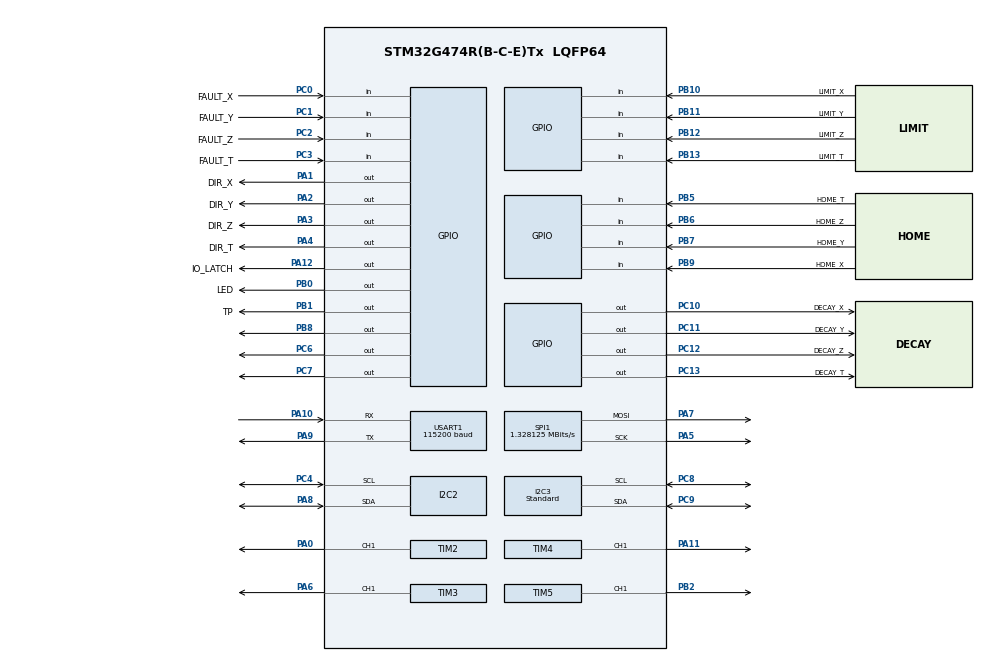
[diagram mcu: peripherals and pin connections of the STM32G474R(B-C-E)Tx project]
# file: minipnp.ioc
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Dma.Request0=USART1_TX
Dma.USART1_TX.0.Direction=DMA_MEMORY_TO_PERIPH
Dma.USART1_TX.0.EventEnable=DISABLE
Dma.USART1_TX.0.Instance=DMA1_Channel1
Dma.USART1_TX.0.MemDataAlignment=DMA_MDATAALIGN_BYTE
Dma.USART1_TX.0.MemInc=DMA_MINC_ENABLE
Dma.USART1_TX.0.Mode=DMA_NORMAL
Dma.USART1_TX.0.PeriphDataAlignment=DMA_PDATAALIGN_BYTE
Dma.USART1_TX.0.PeriphInc=DMA_PINC_DISABLE
Dma.USART1_TX.0.Polarity=HAL_DMAMUX_REQ_GEN_RISING
Dma.USART1_TX.0.Priority=DMA_PRIORITY_LOW
Dma.USART1_TX.0.RequestNumber=1
Dma.USART1_TX.0.SignalID=NONE
Dma.USART1_TX.0.SyncEnable=DISABLE
Dma.USART1_TX.0.SyncPolarity=HAL_DMAMUX_SYNC_NO_EVENT
Dma.USART1_TX.0.SyncRequestNumber=1
Dma.USART1_TX.0.SyncSignalID=NONE
I2C2.Timing=0x30A0A7FB
I2C3.CustomTiming=Disabled
I2C3.I2C_Speed_Mode=I2C_Standard
I2C3.Timing=0x30A0A7FB
Mcu.Family=STM32G4
Mcu.Name=STM32G474R(B-C-E)Tx
Mcu.Package=LQFP64
NVIC.DMA1_Channel1_IRQn=true\:0\:0\:false\:false\:true\:false\:true
NVIC.PriorityGroup=NVIC_PRIORITYGROUP_4
NVIC.TIM2_IRQn=true\:0\:0\:false\:false\:true\:true\:true
NVIC.TIM3_IRQn=true\:0\:0\:false\:false\:true\:true\:true
NVIC.TIM4_IRQn=true\:0\:0\:false\:false\:true\:true\:true
NVIC.TIM5_IRQn=true\:0\:0\:false\:false\:true\:true\:true
NVIC.TIM6_DAC_IRQn=true\:1\:0\:true\:false\:true\:true\:true
NVIC.USART1_IRQn=true\:2\:0\:true\:false\:true\:true\:true
PA0.Signal=S_TIM2_CH1
PA1.GPIO_Label=DIR_X
PA1.GPIO_Speed=GPIO_SPEED_FREQ_VERY_HIGH
PA1.Signal=GPIO_Output
PA10.Mode=Asynchronous
PA10.Signal=USART1_RX
PA11.Signal=S_TIM4_CH1
PA12.GPIO_Label=IO_LATCH
PA12.GPIO_Speed=GPIO_SPEED_FREQ_VERY_HIGH
PA12.Signal=GPIO_Output
PA13.Mode=JTAG_5_pins
PA13.Signal=SYS_JTMS-SWDIO
PA14.Mode=JTAG_5_pins
PA14.Signal=SYS_JTCK-SWCLK
PA15.Mode=JTAG_5_pins
PA15.Signal=SYS_JTDI
PA2.GPIO_Label=DIR_Y
PA2.GPIO_Speed=GPIO_SPEED_FREQ_VERY_HIGH
PA2.Signal=GPIO_Output
PA3.GPIO_Label=DIR_Z
PA3.GPIO_Speed=GPIO_SPEED_FREQ_VERY_HIGH
PA3.Signal=GPIO_Output
PA4.GPIO_Label=DIR_T
PA4.GPIO_Speed=GPIO_SPEED_FREQ_VERY_HIGH
PA4.Signal=GPIO_Output
PA5.Mode=TX_Only_Simplex_Unidirect_Master
PA5.Signal=SPI1_SCK
PA6.Signal=S_TIM3_CH1
PA7.Mode=TX_Only_Simplex_Unidirect_Master
PA7.Signal=SPI1_MOSI
PA8.GPIO_Pu=GPIO_PULLUP
PA8.Mode=I2C
PA8.Signal=I2C2_SDA
PA9.Mode=Asynchronous
PA9.Signal=USART1_TX
PB0.GPIO_Label=LED
PB0.GPIO_Speed=GPIO_SPEED_FREQ_VERY_HIGH
PB0.Signal=GPIO_Output
PB1.GPIO_Label=TP
PB1.GPIO_Speed=GPIO_SPEED_FREQ_VERY_HIGH
PB1.Signal=GPIO_Output
PB10.GPIO_Label=LIMIT_X
PB10.Signal=GPIO_Input
PB11.GPIO_Label=LIMIT_Y
PB11.Signal=GPIO_Input
PB12.GPIO_Label=LIMIT_Z
PB12.Signal=GPIO_Input
PB13.GPIO_Label=LIMIT_T
PB13.Signal=GPIO_Input
PB2.Signal=S_TIM5_CH1
PB3.Mode=JTAG_5_pins
PB3.Signal=SYS_JTDO-SWO
PB4.Mode=JTAG_5_pins
PB4.Signal=SYS_JTRST
PB5.GPIO_Label=HOME_T
PB5.Signal=GPIO_Input
PB6.GPIO_Label=HOME_Z
PB6.Signal=GPIO_Input
PB7.GPIO_Label=HOME_Y
PB7.Signal=GPIO_Input
PB8-BOOT0.Signal=GPIO_Output
PB9.GPIO_Label=HOME_X
PB9.Signal=GPIO_Input
PC0.GPIO_Label=FAULT_X
PC0.Signal=GPIO_Input
PC1.GPIO_Label=FAULT_Y
PC1.Signal=GPIO_Input
PC10.GPIO_Label=DECAY_X
PC10.Signal=GPIO_Output
PC11.GPIO_Label=DECAY_Y
PC11.Signal=GPIO_Output
PC12.GPIO_Label=DECAY_Z
PC12.Signal=GPIO_Output
PC13.GPIO_Label=DECAY_T
PC13.PinState=GPIO_PIN_RESET
PC13.Signal=GPIO_Output
PC2.GPIO_Label=FAULT_Z
PC2.Signal=GPIO_Input
PC3.GPIO_Label=FAULT_T
PC3.Signal=GPIO_Input
PC4.GPIO_Pu=GPIO_PULLUP
PC4.Mode=I2C
PC4.Signal=I2C2_SCL
PC6.Signal=GPIO_Output
PC7.Signal=GPIO_Output
PC8.GPIO_Pu=GPIO_PULLUP
PC8.Mode=I2C
PC8.Signal=I2C3_SCL
PC9.GPIO_Pu=GPIO_PULLUP
PC9.Mode=I2C
PC9.Signal=I2C3_SDA
PF0-OSC_IN.Signal=ADC1_IN10
ProjectManager.HeapSize=0x200
ProjectManager.StackSize=0x400
ProjectManager.TargetToolchain=STM32CubeIDE
RCC.ADC12Freq_Value=170000000
RCC.ADC345Freq_Value=170000000
RCC.AHBFreq_Value=170000000
RCC.APB1Freq_Value=170000000
RCC.APB1TimFreq_Value=170000000
RCC.APB2Freq_Value=170000000
RCC.APB2TimFreq_Value=170000000
RCC.CortexFreq_Value=170000000
RCC.EXTERNAL_CLOCK_VALUE=12288000
RCC.HCLKFreq_Value=170000000
RCC.HSE_VALUE=8000000
RCC.HSI48_VALUE=48000000
RCC.HSI_VALUE=16000000
RCC.LSE_VALUE=32768
RCC.PLLM=RCC_PLLM_DIV4
RCC.PLLN=85
RCC.SYSCLKFreq_VALUE=170000000
RCC.SYSCLKSource=RCC_SYSCLKSOURCE_PLLCLK
RCC.USBFreq_Value=170000000
RCC.VCOOutputFreq_Value=340000000
SH.S_TIM2_CH1.0=TIM2_CH1,PWM Generation1 CH1
SH.S_TIM3_CH1.0=TIM3_CH1,PWM Generation1 CH1
SH.S_TIM4_CH1.0=TIM4_CH1,PWM Generation1 CH1
SH.S_TIM5_CH1.0=TIM5_CH1,PWM Generation1 CH1
SPI1.BaudRatePrescaler=SPI_BAUDRATEPRESCALER_128
SPI1.CalculateBaudRate=1.328125 MBits/s
SPI1.DataSize=SPI_DATASIZE_8BIT
SPI1.Direction=SPI_DIRECTION_2LINES
SPI1.Mode=SPI_MODE_MASTER
SPI1.NSSPMode=SPI_NSS_PULSE_DISABLE
SPI1.VirtualType=VM_MASTER
TIM2.AutoReloadPreload=TIM_AUTORELOAD_PRELOAD_ENABLE
TIM2.Channel-PWM\ Generation1\ CH1=TIM_CHANNEL_1
TIM2.OC1Preload_PWM=ENABLE
TIM2.OCFastMode_PWM-PWM\ Generation1\ CH1=TIM_OCFAST_ENABLE
TIM2.OCMode_PWM-PWM\ Generation1\ CH1=TIM_OCMODE_PWM2
TIM2.OCPolarity_1=TIM_OCPOLARITY_HIGH
TIM3.AutoReloadPreload=TIM_AUTORELOAD_PRELOAD_ENABLE
TIM3.Channel-PWM\ Generation1\ CH1=TIM_CHANNEL_1
TIM3.OCFastMode_PWM-PWM\ Generation1\ CH1=TIM_OCFAST_ENABLE
TIM3.OCMode_PWM-PWM\ Generation1\ CH1=TIM_OCMODE_PWM2
TIM4.AutoReloadPreload=TIM_AUTORELOAD_PRELOAD_ENABLE
TIM4.Channel-PWM\ Generation1\ CH1=TIM_CHANNEL_1
TIM4.OCFastMode_PWM-PWM\ Generation1\ CH1=TIM_OCFAST_ENABLE
TIM4.OCMode_PWM-PWM\ Generation1\ CH1=TIM_OCMODE_PWM2
TIM5.AutoReloadPreload=TIM_AUTORELOAD_PRELOAD_ENABLE
TIM5.Channel-PWM\ Generation1\ CH1=TIM_CHANNEL_1
TIM5.OCFastMode_PWM-PWM\ Generation1\ CH1=TIM_OCFAST_ENABLE
TIM5.OCMode_PWM-PWM\ Generation1\ CH1=TIM_OCMODE_PWM2
TIM6.AutoReloadPreload=TIM_AUTORELOAD_PRELOAD_ENABLE
TIM6.PeriodNoDither=17000
TIM6.Prescaler=9
USART1.BaudRate=115200
USART1.VirtualMode-Asynchronous=VM_ASYNC
VP_SYS_VS_DBSignals.Mode=DisableDeadBatterySignals
VP_TIM2_VS_ClockSourceINT.Mode=Internal
VP_TIM3_VS_ClockSourceINT.Mode=Internal
VP_TIM4_VS_ClockSourceINT.Mode=Internal
VP_TIM5_VS_ClockSourceINT.Mode=Internal
VP_TIM6_VS_ClockSourceINT.Mode=Enable_Timer
VP_TIM7_VS_ClockSourceINT.Mode=Enable_Timer
VP_TIM7_VS_OPM.Mode=OPM_bit
board=custom

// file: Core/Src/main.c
/* USER CODE BEGIN Header */
/**
  ******************************************************************************
  * @file           : main.c
  * @brief          : Main program body
  ******************************************************************************
  * @attention
  *
  * <h2><center>&copy; Copyright (c) 2020 STMicroelectronics.
  * All rights reserved.</center></h2>
  *
  * This software component is licensed by ST under BSD 3-Clause license,
  * the "License"; You may not use this file except in compliance with the
  * License. You may obtain a copy of the License at:
  *                        opensource.org/licenses/BSD-3-Clause
  *
  ******************************************************************************
  */
/* USER CODE END Header */
#include "main.h"
#include "dma.h"
#include "i2c.h"
#include "spi.h"
#include "tim.h"
#include "usart.h"
#include "gpio.h"

/* USER CODE BEGIN Includes */
#include "ioext.h"
#include "IHMctrl.h"
#include "feeder.h"
/* USER CODE END Includes */

void SystemClock_Config(void);

int main(void)
{

  /* MCU Configuration--------------------------------------------------------*/

  /* Reset of all peripherals, Initializes the Flash interface and the Systick. */
  HAL_Init();

  /* Configure the system clock */
  SystemClock_Config();

  /* Initialize all configured peripherals */
  MX_GPIO_Init();
  MX_I2C2_Init();
  MX_I2C3_Init();
  MX_SPI1_Init();
  MX_TIM2_Init();
  MX_TIM3_Init();
  MX_TIM4_Init();
  MX_TIM5_Init();
  MX_USART1_UART_Init();
  MX_TIM6_Init();
  MX_DMA_Init();
  MX_TIM7_Init();
  /* USER CODE BEGIN 2 */
  myInitTIM();
  mySpiInit();
  myUsartInit();
  myI2Cinit();
  /* USER CODE END 2 */

  /* Infinite loop */
  /* USER CODE BEGIN WHILE */
  initExtIo();
  LL_GPIO_SetOutputPin(DECAY_X_GPIO_Port, DECAY_X_Pin);
  IHMctrlInit();
/*	char name[40];
	feederGetStatus(0x20);
	feederGetStatus(0x20);
	feederGetStatus(0x40);
	feederGetStatus(0x77);
	feederGetName(0x20, name);*/
 // unsigned char valOut = 10;
  //I2CWrite(I2C3,0x02, 0x01,1, &valOut);

  while (1)
  {
	  appLoop();
    /* USER CODE END WHILE */

  }
}

void SystemClock_Config(void)
{
  LL_FLASH_SetLatency(LL_FLASH_LATENCY_4);
  while(LL_FLASH_GetLatency() != LL_FLASH_LATENCY_4)
  {
  }
  LL_PWR_EnableRange1BoostMode();
  LL_RCC_HSI_Enable();
   /* Wait till HSI is ready */
  while(LL_RCC_HSI_IsReady() != 1)
  {
  }

  LL_RCC_HSI_SetCalibTrimming(64);
  LL_RCC_PLL_ConfigDomain_SYS(LL_RCC_PLLSOURCE_HSI, LL_RCC_PLLM_DIV_4, 85, LL_RCC_PLLR_DIV_2);
  LL_RCC_PLL_EnableDomain_SYS();
  LL_RCC_PLL_Enable();
   /* Wait till PLL is ready */
  while(LL_RCC_PLL_IsReady() != 1)
  {
  }

  LL_RCC_SetSysClkSource(LL_RCC_SYS_CLKSOURCE_PLL);
  LL_RCC_SetAHBPrescaler(LL_RCC_SYSCLK_DIV_2);
   /* Wait till System clock is ready */
  while(LL_RCC_GetSysClkSource() != LL_RCC_SYS_CLKSOURCE_STATUS_PLL)
  {
  }

  /* Insure 1µs transition state at intermediate medium speed clock based on DWT */
  CoreDebug->DEMCR |= CoreDebug_DEMCR_TRCENA_Msk;
  DWT->CTRL |= DWT_CTRL_CYCCNTENA_Msk;
  DWT->CYCCNT = 0;
  while(DWT->CYCCNT < 100);
  /* Set AHB prescaler*/
  LL_RCC_SetAHBPrescaler(LL_RCC_SYSCLK_DIV_1);
  LL_RCC_SetAPB1Prescaler(LL_RCC_APB1_DIV_1);
  LL_RCC_SetAPB2Prescaler(LL_RCC_APB2_DIV_1);
  LL_SetSystemCoreClock(170000000);

   /* Update the time base */
  if (HAL_InitTick (TICK_INT_PRIORITY) != HAL_OK)
  {
    Error_Handler();
  }
}

void Error_Handler(void)
{
}
